# M462 register map
File version: 0.1
Registers are 32-bit, read-write, reset 0x0 unless marked. A register's access mark holds for its fields unless they carry their own. Offsets are from the block's base; [hi:lo] are bit positions; {n}, {i} and the like mark numbered series.

## PA — Port A
Base 0x402C0000
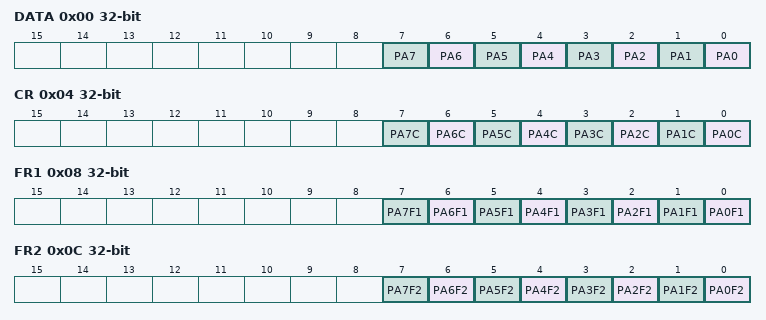
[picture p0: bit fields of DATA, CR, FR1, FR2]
0x00 DATA — Port A Data Register
  [n] PA{n} (n=0..7)
0x04 CR — Port A Output Control Register
  [n] PA{n}C (n=0..7)
0x08 FR1 — Port A Function Register 1
  [n] PA{n}F1 (n=0..7)
0x0C FR2 — Port A Function Register 2
  [n] PA{n}F2 (n=0..7)
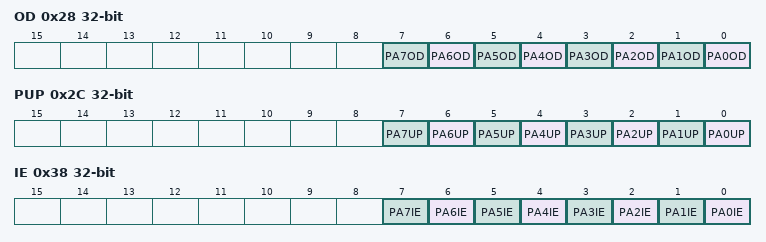
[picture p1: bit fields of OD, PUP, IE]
0x28 OD — Port A Open Drain Control Register
  [n] PA{n}OD (n=0..7)
0x2C PUP — Port A Pull-up Control Register
  [n] PA{n}UP (n=0..7)
0x38 IE — Port A Input Control Register
  [n] PA{n}IE (n=0..7)

## PB — Port B
Base 0x402C0100
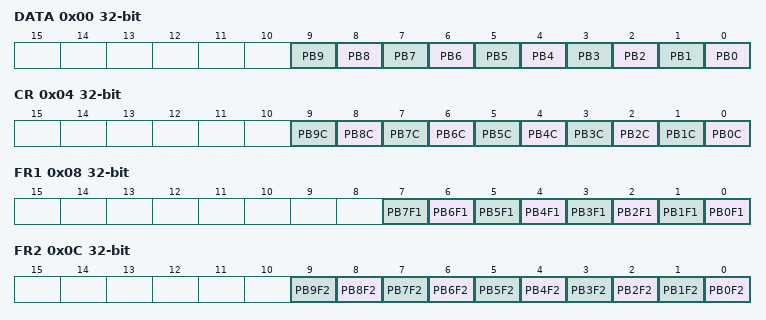
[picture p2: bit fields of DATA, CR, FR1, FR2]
0x00 DATA — Port B Data Register
  [n] PB{n} (n=0..9)
0x04 CR — Port B Output Control Register
  [n] PB{n}C (n=0..9)
0x08 FR1 — Port B Function Register 1
  [n] PB{n}F1 (n=0..7)
0x0C FR2 — Port B Function Register 2
  [n] PB{n}F2 (n=0..9)
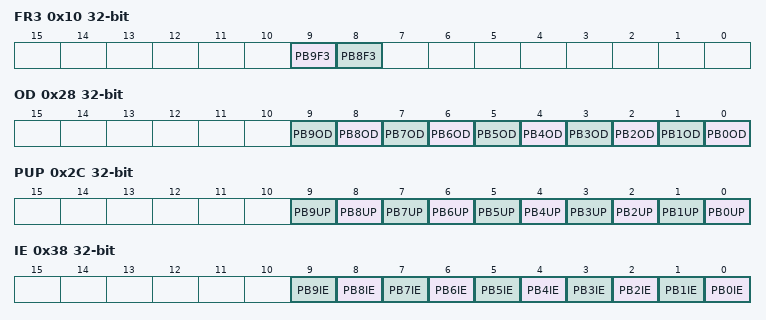
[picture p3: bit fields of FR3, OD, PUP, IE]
0x10 FR3 — Port B Function Register 3
  [9] PB9F3, [8] PB8F3
0x28 OD — Port B Open Drain Control Register
  [n] PB{n}OD (n=0..9)
0x2C PUP — Port B Pull-up Control Register
  [n] PB{n}UP (n=0..9)
0x38 IE — Port B Input Control Register
  [n] PB{n}IE (n=0..9)

## PC — Port C
Base 0x402C0200
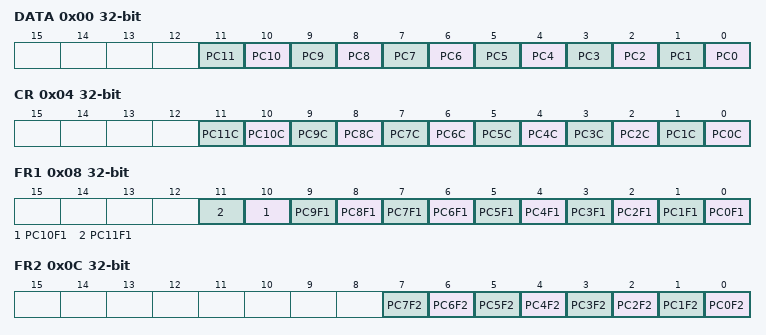
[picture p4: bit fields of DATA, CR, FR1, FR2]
0x00 DATA — Port C Data Register
  [n] PC{n} (n=0..11)
0x04 CR — Port C Output Control Register
  [n] PC{n}C (n=0..11)
0x08 FR1 — Port C Function Register 1
  [n] PC{n}F1 (n=0..11)
0x0C FR2 — Port C Function Register 2
  [n] PC{n}F2 (n=0..7)
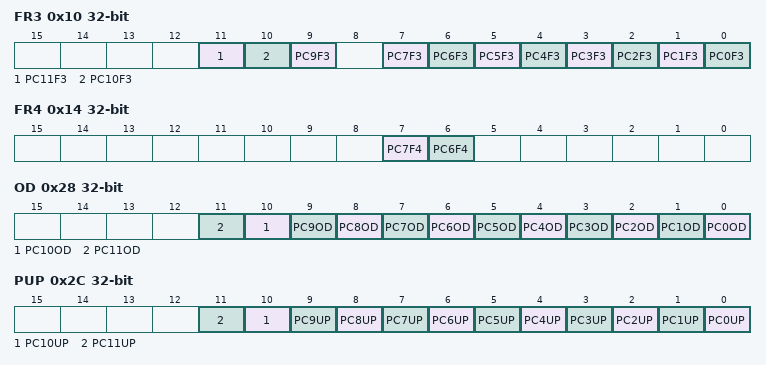
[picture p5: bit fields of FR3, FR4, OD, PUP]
0x10 FR3 — Port C Function Register 3
  [11] PC11F3, [10] PC10F3, [9] PC9F3, [n] PC{n}F3 (n=0..7)
0x14 FR4 — Port C Function Register 4
  [7] PC7F4, [6] PC6F4
0x28 OD — Port C Open Drain Control Register
  [n] PC{n}OD (n=0..11)
0x2C PUP — Port C Pull-up Control Register
  [n] PC{n}UP (n=0..11)
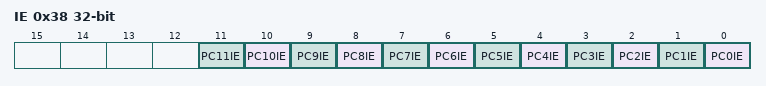
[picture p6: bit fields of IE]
0x38 IE — Port C Input Control Register
  [n] PC{n}IE (n=0..11)

## PD — Port D
Base 0x402C0300
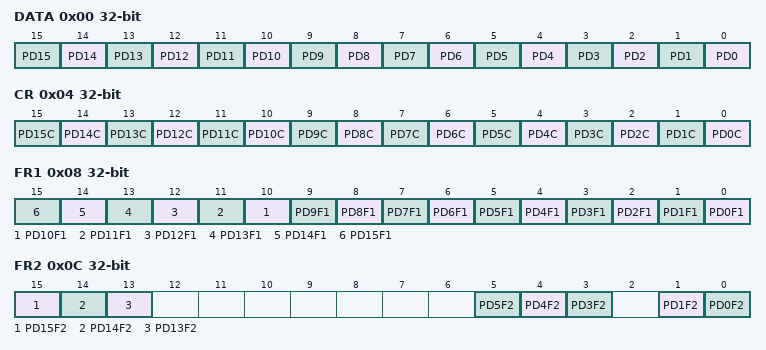
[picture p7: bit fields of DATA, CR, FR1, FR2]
0x00 DATA — Port D Data Register
  [n] PD{n} (n=0..15)
0x04 CR — Port D Output Control Register
  [n] PD{n}C (n=0..15)
0x08 FR1 — Port D Function Register 1
  [n] PD{n}F1 (n=0..15)
0x0C FR2 — Port D Function Register 2
  [15] PD15F2, [14] PD14F2, [13] PD13F2, [5] PD5F2, [4] PD4F2, [3] PD3F2, [1] PD1F2, [0] PD0F2
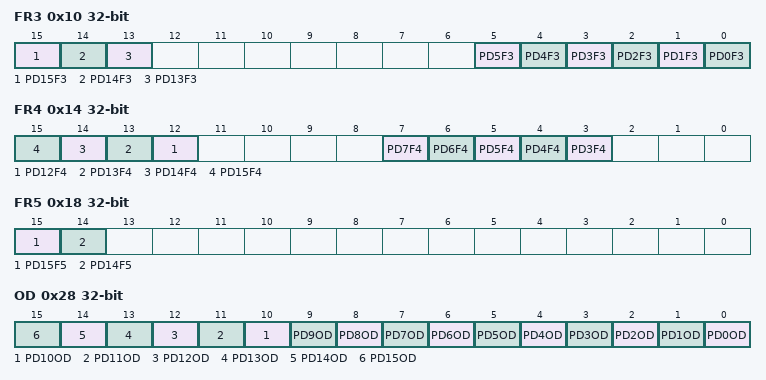
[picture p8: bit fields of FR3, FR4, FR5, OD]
0x10 FR3 — Port D Function Register 3
  [15] PD15F3, [14] PD14F3, [13] PD13F3, [n] PD{n}F3 (n=0..5)
0x14 FR4 — Port D Function Register 4
  [n] PD{n}F4 (n=12..15), [n] PD{n}F4 (n=3..7)
0x18 FR5 — Port D Function Register 5
  [15] PD15F5, [14] PD14F5
0x28 OD — Port D Open Drain Control Register
  [n] PD{n}OD (n=0..15)
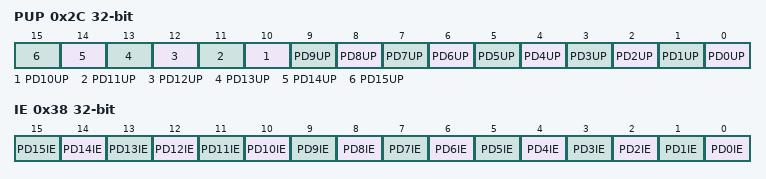
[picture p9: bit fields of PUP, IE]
0x2C PUP — Port D Pull-up Control Register
  [n] PD{n}UP (n=0..15)
0x38 IE — Port D Input Control Register
  [n] PD{n}IE (n=0..15)

## PE — Port E
Base 0x402C0400
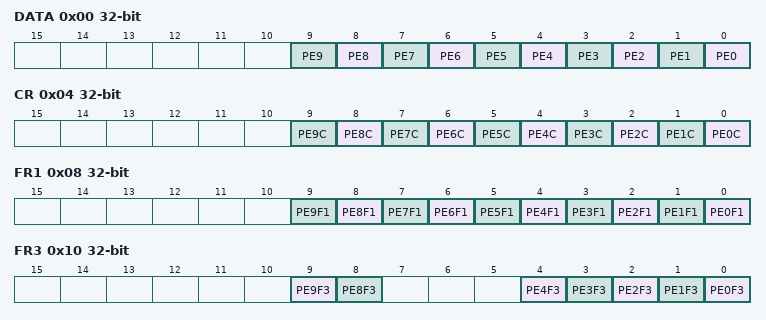
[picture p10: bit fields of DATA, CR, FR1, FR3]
0x00 DATA — Port E Data Register
  [n] PE{n} (n=0..9)
0x04 CR — Port E Output Control Register
  [n] PE{n}C (n=0..9)
0x08 FR1 — Port E Function Register 1
  [n] PE{n}F1 (n=0..9)
0x0C FR2 — Port E Function Register 2
  [0] PE0F2
0x10 FR3 — Port E Function Register 3
  [9] PE9F3, [8] PE8F3, [n] PE{n}F3 (n=0..4)
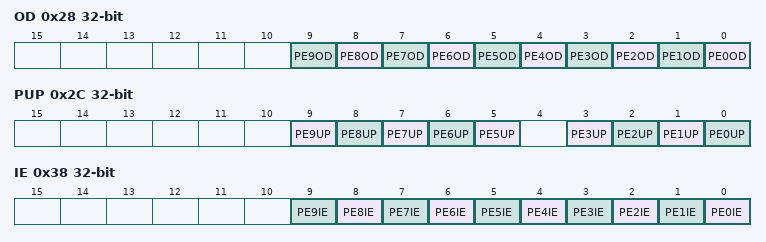
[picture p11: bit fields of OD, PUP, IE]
0x28 OD — Port E Open Drain Control Register
  [n] PE{n}OD (n=0..9)
0x2C PUP — Port E Pull-up Control Register
  [n] PE{n}UP (n=5..9), [n] PE{n}UP (n=0..3)
0x30 PDN — Port E Pull-down Control Register
  [4] PE4DN
0x38 IE — Port E Input Control Register
  [n] PE{n}IE (n=0..9)

## PF — Port F
Base 0x402C0500
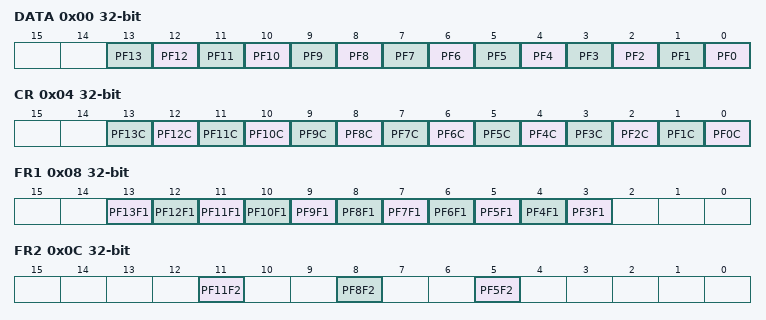
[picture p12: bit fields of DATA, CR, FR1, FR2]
0x00 DATA — Port F Data Register
  [n] PF{n} (n=0..13)
0x04 CR — Port F Output Control Register
  [n] PF{n}C (n=0..13)
0x08 FR1 — Port F Function Register 1
  [n] PF{n}F1 (n=3..13)
0x0C FR2 — Port F Function Register 2
  [11] PF11F2, [8] PF8F2, [5] PF5F2
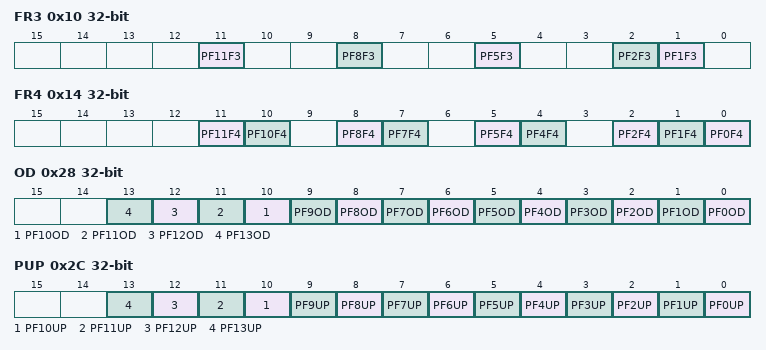
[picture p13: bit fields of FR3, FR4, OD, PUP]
0x10 FR3 — Port F Function Register 3
  [11] PF11F3, [8] PF8F3, [5] PF5F3, [2] PF2F3, [1] PF1F3
0x14 FR4 — Port F Function Register 4
  [11] PF11F4, [10] PF10F4, [8] PF8F4, [7] PF7F4, [5] PF5F4, [4] PF4F4, [2] PF2F4, [1] PF1F4, [0] PF0F4
0x28 OD — Port F Open Drain Control Register
  [n] PF{n}OD (n=0..13)
0x2C PUP — Port E Pull-up Control Register
  [n] PF{n}UP (n=0..13)
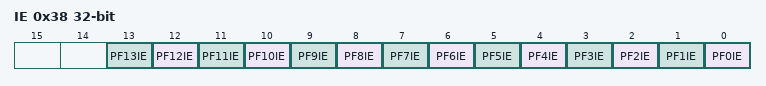
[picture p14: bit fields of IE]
0x38 IE — Port F Input Control Register
  [n] PF{n}IE (n=0..13)
